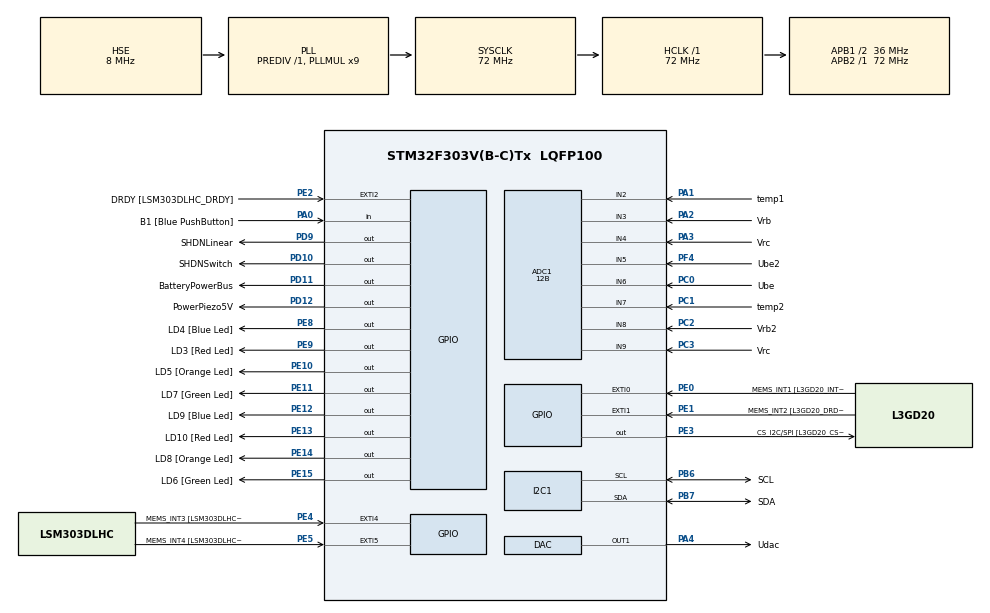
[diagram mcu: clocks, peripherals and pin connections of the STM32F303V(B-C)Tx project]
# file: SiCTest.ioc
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ADC1.AutoInjectedConv=DISABLE
ADC1.Channel-0\#ChannelRegularConversion=ADC_CHANNEL_2
ADC1.ClockPrescaler=ADC_CLOCK_ASYNC_DIV1
ADC1.ContinuousConvMode=DISABLE
ADC1.DMAContinuousRequests=DISABLE
ADC1.DataAlign=ADC_DATAALIGN_RIGHT
ADC1.DiscontinuousConvMode=DISABLE
ADC1.EOCSelection=ADC_EOC_SINGLE_CONV
ADC1.EnableAnalogWatchDog1=false
ADC1.EnableAnalogWatchDog2=false
ADC1.EnableAnalogWatchDog3=false
ADC1.EnableInjectedConversion=ENABLE
ADC1.EnableRegularConversion=ENABLE
ADC1.ExternalTrigConv=ADC_SOFTWARE_START
ADC1.ExternalTrigConvEdge=ADC_EXTERNALTRIGCONVEDGE_NONE
ADC1.InjNumberOfConversion=0
ADC1.InjectedDiscontinuousConvMode=DISABLE
ADC1.LowPowerAutoWait=DISABLE
ADC1.NbrOfConversion=1
ADC1.NbrOfConversionFlag=1
ADC1.Offset-0\#ChannelRegularConversion=0
ADC1.OffsetNumber-0\#ChannelRegularConversion=ADC_OFFSET_NONE
ADC1.Overrun=ADC_OVR_DATA_OVERWRITTEN
ADC1.Rank-0\#ChannelRegularConversion=1
ADC1.Resolution=ADC_RESOLUTION_12B
ADC1.SamplingTime-0\#ChannelRegularConversion=ADC_SAMPLETIME_1CYCLE_5
ADC1.ScanConvMode=ADC_SCAN_DISABLE
ADC1.SingleDiff-0\#ChannelRegularConversion=ADC_SINGLE_ENDED
ADC1.master=1
DAC.DAC_Channel=DAC_CHANNEL_1
DAC.WaveGeneration=DISABLE
I2C1.OwnAddress2Masks=I2C_OA2_NOMASK
I2C1.Timing=0x2000090E
Mcu.Family=STM32F3
Mcu.Name=STM32F303V(B-C)Tx
Mcu.Package=LQFP100
NVIC.PriorityGroup=NVIC_PRIORITYGROUP_0
PA0.GPIO_Label=B1 [Blue PushButton]
PA0.GPIO_Mode=GPIO_MODE_INPUT
PA0.GPIO_PuPd=GPIO_NOPULL
PA0.Signal=GPIO_Input
PA1.GPIO_Label=temp1
PA1.GPIO_PuPd=GPIO_NOPULL
PA1.Mode=IN2-Single-Ended
PA1.Signal=ADC1_IN2
PA11.GPIO_Label=DM
PA11.Signal=USB_DM
PA12.GPIO_Label=DP
PA12.Signal=USB_DP
PA13.Signal=SYS_JTMS-SWDIO
PA14.Signal=SYS_JTCK-SWCLK
PA2.GPIO_Label=Vrb
PA2.Mode=IN3-Single-Ended
PA2.Signal=ADC1_IN3
PA3.GPIO_Label=Vrc
PA3.Mode=IN4-Single-Ended
PA3.Signal=ADC1_IN4
PA4.GPIO_Label=Udac
PA4.Signal=COMP_DAC1_group
PA5.GPIO_Label=SPI1_SCK [L3GD20_SCL/SPC]
PA5.GPIO_Mode=GPIO_MODE_AF_PP
PA5.GPIO_PuPd=GPIO_NOPULL
PA5.GPIO_Speed=GPIO_SPEED_FREQ_LOW
PA5.Signal=SPI1_SCK
PA6.GPIO_Label=SPI1_MISO [L3GD20_SA0/SDO]
PA6.GPIO_Mode=GPIO_MODE_AF_PP
PA6.GPIO_PuPd=GPIO_NOPULL
PA6.GPIO_Speed=GPIO_SPEED_FREQ_LOW
PA6.Signal=SPI1_MISO
PA7.GPIO_Label=SPI1_MISO [L3GD20_SDA/SDI/SDO]
PA7.GPIO_Mode=GPIO_MODE_AF_PP
PA7.GPIO_PuPd=GPIO_NOPULL
PA7.GPIO_Speed=GPIO_SPEED_FREQ_LOW
PA7.Signal=SPI1_MOSI
PB3.Signal=SYS_JTDO-TRACESWO
PB6.GPIO_FM6=__NULL
PB6.GPIO_Label=SCL
PB6.GPIO_Mode=GPIO_MODE_AF_OD
PB6.GPIO_PuPd=GPIO_NOPULL
PB6.GPIO_Speed=GPIO_SPEED_FREQ_LOW
PB6.Mode=I2C
PB6.Signal=I2C1_SCL
PB7.GPIO_FM7=__NULL
PB7.GPIO_Label=SDA
PB7.GPIO_Mode=GPIO_MODE_AF_OD
PB7.GPIO_PuPd=GPIO_NOPULL
PB7.GPIO_Speed=GPIO_SPEED_FREQ_LOW
PB7.Mode=I2C
PB7.Signal=I2C1_SDA
PC0.GPIO_Label=Ube
PC0.Signal=ADCx_IN6
PC1.GPIO_Label=temp2
PC1.Signal=ADCx_IN7
PC14-OSC32_IN.GPIO_Label=OSC32_IN
PC14-OSC32_IN.Signal=RCC_OSC32_IN
PC15-OSC32_OUT.GPIO_Label=OSC32_OUT
PC15-OSC32_OUT.Signal=RCC_OSC32_OUT
PC2.GPIO_Label=Vrb2
PC2.Signal=ADCx_IN8
PC3.GPIO_Label=Vrc
PC3.Signal=ADCx_IN9
PD10.GPIO_Label=SHDNSwitch
PD10.GPIO_PuPd=GPIO_PULLUP
PD10.PinState=GPIO_PIN_SET
PD10.Signal=GPIO_Output
PD11.GPIO_Label=BatteryPowerBus
PD11.GPIO_PuPd=GPIO_PULLUP
PD11.PinState=GPIO_PIN_SET
PD11.Signal=GPIO_Output
PD12.GPIO_Label=PowerPiezo5V
PD12.GPIO_ModeDefaultOutputPP=GPIO_MODE_OUTPUT_PP
PD12.GPIO_PuPd=GPIO_NOPULL
PD12.PinState=GPIO_PIN_SET
PD12.Signal=GPIO_Output
PD9.GPIO_Label=SHDNLinear
PD9.GPIO_PuPd=GPIO_PULLUP
PD9.PinState=GPIO_PIN_SET
PD9.Signal=GPIO_Output
PE0.GPIO_Label=MEMS_INT1 [L3GD20_INT1]
PE0.GPIO_ModeDefaultEXTI=GPIO_MODE_EVT_RISING
PE0.GPIO_PuPd=GPIO_NOPULL
PE0.Signal=GPXTI0
PE1.GPIO_Label=MEMS_INT2 [L3GD20_DRDY/INT2]
PE1.GPIO_ModeDefaultEXTI=GPIO_MODE_EVT_RISING
PE1.GPIO_PuPd=GPIO_NOPULL
PE1.Signal=GPXTI1
PE10.GPIO_Label=LD5 [Orange Led]
PE10.GPIO_ModeDefaultOutputPP=GPIO_MODE_OUTPUT_PP
PE10.GPIO_PuPd=GPIO_NOPULL
PE10.GPIO_Speed=GPIO_SPEED_FREQ_LOW
PE10.Signal=GPIO_Output
PE11.GPIO_Label=LD7 [Green Led]
PE11.GPIO_ModeDefaultOutputPP=GPIO_MODE_OUTPUT_PP
PE11.GPIO_PuPd=GPIO_NOPULL
PE11.GPIO_Speed=GPIO_SPEED_FREQ_LOW
PE11.Signal=GPIO_Output
PE12.GPIO_Label=LD9 [Blue Led]
PE12.GPIO_ModeDefaultOutputPP=GPIO_MODE_OUTPUT_PP
PE12.GPIO_PuPd=GPIO_NOPULL
PE12.GPIO_Speed=GPIO_SPEED_FREQ_LOW
PE12.Signal=GPIO_Output
PE13.GPIO_Label=LD10 [Red Led]
PE13.GPIO_ModeDefaultOutputPP=GPIO_MODE_OUTPUT_PP
PE13.GPIO_PuPd=GPIO_NOPULL
PE13.GPIO_Speed=GPIO_SPEED_FREQ_LOW
PE13.Signal=GPIO_Output
PE14.GPIO_Label=LD8 [Orange Led]
PE14.GPIO_ModeDefaultOutputPP=GPIO_MODE_OUTPUT_PP
PE14.GPIO_PuPd=GPIO_NOPULL
PE14.GPIO_Speed=GPIO_SPEED_FREQ_LOW
PE14.Signal=GPIO_Output
PE15.GPIO_Label=LD6 [Green Led]
PE15.GPIO_ModeDefaultOutputPP=GPIO_MODE_OUTPUT_PP
PE15.GPIO_PuPd=GPIO_NOPULL
PE15.GPIO_Speed=GPIO_SPEED_FREQ_LOW
PE15.Signal=GPIO_Output
PE2.GPIO_Label=DRDY [LSM303DLHC_DRDY]
PE2.GPIO_ModeDefaultEXTI=GPIO_MODE_EVT_RISING
PE2.GPIO_PuPd=GPIO_NOPULL
PE2.Signal=GPXTI2
PE3.GPIO_Label=CS_I2C/SPI [L3GD20_CS_I2C/SPI]
PE3.GPIO_ModeDefaultOutputPP=GPIO_MODE_OUTPUT_PP
PE3.GPIO_PuPd=GPIO_NOPULL
PE3.GPIO_Speed=GPIO_SPEED_FREQ_LOW
PE3.Signal=GPIO_Output
PE4.GPIO_Label=MEMS_INT3 [LSM303DLHC_INT1]
PE4.GPIO_ModeDefaultEXTI=GPIO_MODE_EVT_RISING
PE4.GPIO_PuPd=GPIO_NOPULL
PE4.Signal=GPXTI4
PE5.GPIO_Label=MEMS_INT4 [LSM303DLHC_INT2]
PE5.GPIO_ModeDefaultEXTI=GPIO_MODE_EVT_RISING
PE5.GPIO_PuPd=GPIO_NOPULL
PE5.Signal=GPXTI5
PE8.GPIO_Label=LD4 [Blue Led]
PE8.GPIO_ModeDefaultOutputPP=GPIO_MODE_OUTPUT_PP
PE8.GPIO_PuPd=GPIO_NOPULL
PE8.GPIO_Speed=GPIO_SPEED_FREQ_LOW
PE8.Signal=GPIO_Output
PE9.GPIO_Label=LD3 [Red Led]
PE9.GPIO_ModeDefaultOutputPP=GPIO_MODE_OUTPUT_PP
PE9.GPIO_PuPd=GPIO_NOPULL
PE9.GPIO_Speed=GPIO_SPEED_FREQ_LOW
PE9.Signal=GPIO_Output
PF0-OSC_IN.Mode=HSE-External-Oscillator
PF0-OSC_IN.Signal=RCC_OSC_IN
PF1-OSC_OUT.GPIO_Label=OSC_OUT
PF1-OSC_OUT.Mode=HSE-External-Oscillator
PF1-OSC_OUT.Signal=RCC_OSC_OUT
PF4.GPIO_Label=Ube2
PF4.Mode=IN5-Single-Ended
PF4.Signal=ADC1_IN5
ProjectManager.HeapSize=0x200
ProjectManager.StackSize=0x400
ProjectManager.TargetToolchain=EWARM
RCC.ADC1Enable=true
RCC.ADC2Enable=false
RCC.ADC3Enable=false
RCC.ADC4Enable=false
RCC.AHBCLKDivider=RCC_SYSCLK_DIV1
RCC.AHBFreq_Value=72000000
RCC.APB1CLKDivider=RCC_HCLK_DIV2
RCC.APB1Freq_Value=36000000
RCC.APB1TimFreq_Value=72000000
RCC.APB2Freq_Value=72000000
RCC.APB2TimFreq_Value=72000000
RCC.ClockTypeHCLK=RCC_CLOCKTYPE_HCLK
RCC.ClockTypePCLK1=RCC_CLOCKTYPE_PCLK1
RCC.ClockTypePCLK2=RCC_CLOCKTYPE_PCLK2
RCC.CortexFreq_Value=72000000
RCC.EnableHSE=true
RCC.EnableHSERTCDevisor=false
RCC.EnableHSIRTCDevisor=false
RCC.EnableLSE=false
RCC.EnableLSERTC=false
RCC.EnableMCOMultDivisor=false
RCC.EnbaleCSS=true
RCC.FLITFCLKFEnable=false
RCC.HCLKFreq_Value=72000000
RCC.HRTIMEnable=false
RCC.HSEState=RCC_HSE_ON
RCC.HSE_VALUE=8000000
RCC.HSIState=RCC_HSI_ON
RCC.HSI_VALUE=8000000
RCC.I2C1Enable=true
RCC.I2C2Enable=false
RCC.I2C3Enable=false
RCC.I2SEnable=false
RCC.IWDGEnable=false
RCC.LSE_VALUE=32768
RCC.LSIState=RCC_LSI_OFF
RCC.MCOEnable=false
RCC.OscillatorTypeHSE=RCC_OSCILLATORTYPE_HSE
RCC.OscillatorTypeHSI=RCC_OSCILLATORTYPE_HSI
RCC.PLLMUL=RCC_PLL_MUL9
RCC.PLLSource=RCC_PLLSOURCE_HSE
RCC.PLLSourceVirtual=RCC_PLLSOURCE_HSE
RCC.PLLState=RCC_PLL_ON
RCC.RCC_PERIPHCLK_I2C1Var=RCC_PERIPHCLK_I2C1
RCC.RTCEnable=false
RCC.SYSCLKFreq_VALUE=72000000
RCC.SYSCLKSource=RCC_SYSCLKSOURCE_PLLCLK
RCC.SYSCLKSourceVirtual=RCC_SYSCLKSOURCE_PLLCLK
RCC.Tim15Enable=false
RCC.Tim16Enable=false
RCC.Tim17Enable=false
RCC.Tim1Enable=false
RCC.Tim8Enable=false
RCC.UART4Enable=false
RCC.UART5Enable=false
RCC.USART1Enable=false
RCC.USART2Enable=false
RCC.USART3Enable=false
RCC.USBEnable=false
RCC.USBFreq_Value=72000000
SH.ADCx_IN6.0=ADC1_IN6,IN6-Single-Ended
SH.ADCx_IN7.0=ADC1_IN7,IN7-Single-Ended
SH.ADCx_IN8.0=ADC1_IN8,IN8-Single-Ended
SH.ADCx_IN9.0=ADC1_IN9,IN9-Single-Ended
SH.COMP_DAC1_group.0=DAC_OUT1,DAC_OUT1
VP_ADC1_Vref_Input.Mode=IN-Vrefint
board=STM32F3DISCOVERY

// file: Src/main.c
/**
  ******************************************************************************
  * File Name          : main.c
  * Description        : Test program that will simulate the OBC onboard the MIST Satellite
  ******************************************************************************
  *

    This is a test program which has the purpose to simulate the OBC onboard the MIST satellite.
    The main program will start sending commands via I2C to the SiC MCU for which message it
    sends will test the functions that are implemented on the hardware of the SiC PCB.

  * COPYRIGHT(c) 2017 STMicroelectronics
  *
  * Redistribution and use in source and binary forms, with or without modification,
  * are permitted provided that the following conditions are met:
  *   1. Redistributions of source code must retain the above copyright notice,
  *      this list of conditions and the following disclaimer.
  *   2. Redistributions in binary form must reproduce the above copyright notice,
  *      this list of conditions and the following disclaimer in the documentation
  *      and/or other materials provided with the distribution.
  *   3. Neither the name of STMicroelectronics nor the names of its contributors
  *      may be used to endorse or promote products derived from this software
  *      without specific prior written permission.
  *
  * THIS SOFTWARE IS PROVIDED BY THE COPYRIGHT HOLDERS AND CONTRIBUTORS "AS IS"
  * AND ANY EXPRESS OR IMPLIED WARRANTIES, INCLUDING, BUT NOT LIMITED TO, THE
  * IMPLIED WARRANTIES OF MERCHANTABILITY AND FITNESS FOR A PARTICULAR PURPOSE ARE
  * DISCLAIMED. IN NO EVENT SHALL THE COPYRIGHT HOLDER OR CONTRIBUTORS BE LIABLE
  * FOR ANY DIRECT, INDIRECT, INCIDENTAL, SPECIAL, EXEMPLARY, OR CONSEQUENTIAL
  * DAMAGES (INCLUDING, BUT NOT LIMITED TO, PROCUREMENT OF SUBSTITUTE GOODS OR
  * SERVICES; LOSS OF USE, DATA, OR PROFITS; OR BUSINESS INTERRUPTION) HOWEVER
  * CAUSED AND ON ANY THEORY OF LIABILITY, WHETHER IN CONTRACT, STRICT LIABILITY,
  * OR TORT (INCLUDING NEGLIGENCE OR OTHERWISE) ARISING IN ANY WAY OUT OF THE USE
  * OF THIS SOFTWARE, EVEN IF ADVISED OF THE POSSIBILITY OF SUCH DAMAGE.
  *
  ******************************************************************************
  */
#include "main.h"
#include "stm32f3xx_hal.h"
#include "functions.h"

ADC_HandleTypeDef hadc1;

DAC_HandleTypeDef hdac;

I2C_HandleTypeDef hi2c1;

/* USER CODE BEGIN PV */
/* Private variables ---------------------------------------------------------*/

/* USER CODE END PV */

void SystemClock_Config(void);
void Error_Handler(void);
static void MX_GPIO_Init(void);
static void MX_ADC1_Init(void);
static void MX_DAC_Init(void);
static void MX_I2C1_Init(void);

/* USER CODE BEGIN PFP */
/* Private function prototypes -----------------------------------------------*/
extern experiment_package experiments[8];

/* USER CODE END PFP */

int main(void)
{

  /* MCU Configuration----------------------------------------------------------*/

  /* Reset of all peripherals, Initializes the Flash interface and the Systick. */
  HAL_Init();

  /* Configure the system clock */
  SystemClock_Config();

  /* Initialize all configured peripherals */
  MX_GPIO_Init();
  MX_ADC1_Init();
  MX_DAC_Init();
  MX_I2C1_Init();

  while(1)
  {
   // To start the test program push the User Button on the board
     User_Button();
   // Test function that will test all the functions on the SiC PCB
     Test_SiC();

}

}

/** System Clock Configuration
*/
void SystemClock_Config(void)
{

  RCC_OscInitTypeDef RCC_OscInitStruct;
  RCC_ClkInitTypeDef RCC_ClkInitStruct;
  RCC_PeriphCLKInitTypeDef PeriphClkInit;

    /**Initializes the CPU, AHB and APB busses clocks
    */
  RCC_OscInitStruct.OscillatorType = RCC_OSCILLATORTYPE_HSI|RCC_OSCILLATORTYPE_HSE;
  RCC_OscInitStruct.HSEState = RCC_HSE_ON;
  RCC_OscInitStruct.HSEPredivValue = RCC_HSE_PREDIV_DIV1;
  RCC_OscInitStruct.HSIState = RCC_HSI_ON;
  RCC_OscInitStruct.HSICalibrationValue = 16;
  RCC_OscInitStruct.PLL.PLLState = RCC_PLL_ON;
  RCC_OscInitStruct.PLL.PLLSource = RCC_PLLSOURCE_HSE;
  RCC_OscInitStruct.PLL.PLLMUL = RCC_PLL_MUL9;
  if (HAL_RCC_OscConfig(&RCC_OscInitStruct) != HAL_OK)
  {
    Error_Handler();
  }

    /**Initializes the CPU, AHB and APB busses clocks
    */
  RCC_ClkInitStruct.ClockType = RCC_CLOCKTYPE_HCLK|RCC_CLOCKTYPE_SYSCLK
                              |RCC_CLOCKTYPE_PCLK1|RCC_CLOCKTYPE_PCLK2;
  RCC_ClkInitStruct.SYSCLKSource = RCC_SYSCLKSOURCE_PLLCLK;
  RCC_ClkInitStruct.AHBCLKDivider = RCC_SYSCLK_DIV1;
  RCC_ClkInitStruct.APB1CLKDivider = RCC_HCLK_DIV2;
  RCC_ClkInitStruct.APB2CLKDivider = RCC_HCLK_DIV1;

  if (HAL_RCC_ClockConfig(&RCC_ClkInitStruct, FLASH_LATENCY_2) != HAL_OK)
  {
    Error_Handler();
  }

  PeriphClkInit.PeriphClockSelection = RCC_PERIPHCLK_I2C1|RCC_PERIPHCLK_ADC12;
  PeriphClkInit.Adc12ClockSelection = RCC_ADC12PLLCLK_DIV1;
  PeriphClkInit.I2c1ClockSelection = RCC_I2C1CLKSOURCE_HSI;
  if (HAL_RCCEx_PeriphCLKConfig(&PeriphClkInit) != HAL_OK)
  {
    Error_Handler();
  }

    /**Enables the Clock Security System
    */
  HAL_RCC_EnableCSS();

    /**Configure the Systick interrupt time
    */
  HAL_SYSTICK_Config(HAL_RCC_GetHCLKFreq()/1000);

    /**Configure the Systick
    */
  HAL_SYSTICK_CLKSourceConfig(SYSTICK_CLKSOURCE_HCLK);

  /* SysTick_IRQn interrupt configuration */
  HAL_NVIC_SetPriority(SysTick_IRQn, 0, 0);
}

/* ADC1 init function */
static void MX_ADC1_Init(void)
{

  ADC_MultiModeTypeDef multimode;
  ADC_ChannelConfTypeDef sConfig;

    /**Common config
    */
  hadc1.Instance = ADC1;
  hadc1.Init.ClockPrescaler = ADC_CLOCK_ASYNC_DIV1;
  hadc1.Init.Resolution = ADC_RESOLUTION_12B;
  hadc1.Init.ScanConvMode = ADC_SCAN_DISABLE;
  hadc1.Init.ContinuousConvMode = DISABLE;
  hadc1.Init.DiscontinuousConvMode = DISABLE;
  hadc1.Init.ExternalTrigConvEdge = ADC_EXTERNALTRIGCONVEDGE_NONE;
  hadc1.Init.ExternalTrigConv = ADC_SOFTWARE_START;
  hadc1.Init.DataAlign = ADC_DATAALIGN_RIGHT;
  hadc1.Init.NbrOfConversion = 1;
  hadc1.Init.DMAContinuousRequests = DISABLE;
  hadc1.Init.EOCSelection = ADC_EOC_SINGLE_CONV;
  hadc1.Init.LowPowerAutoWait = DISABLE;
  hadc1.Init.Overrun = ADC_OVR_DATA_OVERWRITTEN;
  if (HAL_ADC_Init(&hadc1) != HAL_OK)
  {
    Error_Handler();
  }

    /**Configure the ADC multi-mode
    */
  multimode.Mode = ADC_MODE_INDEPENDENT;
  if (HAL_ADCEx_MultiModeConfigChannel(&hadc1, &multimode) != HAL_OK)
  {
    Error_Handler();
  }

    /**Configure Regular Channel
    */
  sConfig.Channel = ADC_CHANNEL_2;
  sConfig.Rank = 1;
  sConfig.SingleDiff = ADC_SINGLE_ENDED;
  sConfig.SamplingTime = ADC_SAMPLETIME_1CYCLE_5;
  sConfig.OffsetNumber = ADC_OFFSET_NONE;
  sConfig.Offset = 0;
  if (HAL_ADC_ConfigChannel(&hadc1, &sConfig) != HAL_OK)
  {
    Error_Handler();
  }
  /*
sConfig.Channel = ADC_CHANNEL_3;
	if(HAL_ADC_ConfigChannel(&hadc1, &sConfig) != HAL_OK){
		 Error_Handler();
	}

		sConfig.Channel = ADC_CHANNEL_5;
	if(HAL_ADC_ConfigChannel(&hadc1, &sConfig) != HAL_OK){
		 Error_Handler();
	}
		sConfig.Channel = ADC_CHANNEL_6;
	if(HAL_ADC_ConfigChannel(&hadc1, &sConfig) != HAL_OK){
		 Error_Handler();
	}
		sConfig.Channel = ADC_CHANNEL_7;
	if(HAL_ADC_ConfigChannel(&hadc1, &sConfig) != HAL_OK){
		 Error_Handler();
	}

		sConfig.Channel = ADC_CHANNEL_8;
	if(HAL_ADC_ConfigChannel(&hadc1, &sConfig) != HAL_OK){
		 Error_Handler();
	}

	sConfig.Channel = ADC_CHANNEL_9;
	if(HAL_ADC_ConfigChannel(&hadc1, &sConfig) != HAL_OK){
		 Error_Handler();
	}
*/
}

/* DAC init function */
static void MX_DAC_Init(void)
{

  DAC_ChannelConfTypeDef sConfig;

    /**DAC Initialization
    */
  hdac.Instance = DAC;
  if (HAL_DAC_Init(&hdac) != HAL_OK)
  {
    Error_Handler();
  }

    /**DAC channel OUT1 config
    */
  sConfig.DAC_Trigger = DAC_TRIGGER_NONE;
  sConfig.DAC_OutputBuffer = DAC_OUTPUTBUFFER_ENABLE;
  if (HAL_DAC_ConfigChannel(&hdac, &sConfig, DAC_CHANNEL_1) != HAL_OK)
  {
    Error_Handler();
  }

}

/* I2C1 init function */
static void MX_I2C1_Init(void)
{

  hi2c1.Instance = I2C1;
  hi2c1.Init.Timing = 0x2000090E;
  hi2c1.Init.OwnAddress1 = 0x20;
  hi2c1.Init.AddressingMode = I2C_ADDRESSINGMODE_7BIT;
  hi2c1.Init.DualAddressMode = I2C_DUALADDRESS_DISABLE;
  hi2c1.Init.OwnAddress2 = 0;
  hi2c1.Init.OwnAddress2Masks = I2C_OA2_NOMASK;
  hi2c1.Init.GeneralCallMode = I2C_GENERALCALL_DISABLE;
  hi2c1.Init.NoStretchMode = I2C_NOSTRETCH_DISABLE;
  if (HAL_I2C_Init(&hi2c1) != HAL_OK)
  {
    Error_Handler();
  }

    /**Configure Analogue filter
    */
  if (HAL_I2CEx_ConfigAnalogFilter(&hi2c1, I2C_ANALOGFILTER_ENABLE) != HAL_OK)
  {
    Error_Handler();
  }

    /**Configure Digital filter
    */
  if (HAL_I2CEx_ConfigDigitalFilter(&hi2c1, 0) != HAL_OK)
  {
    Error_Handler();
  }

}

/** Configure pins as
        * Analog
        * Input
        * Output
        * EVENT_OUT
        * EXTI
     PA5   ------> SPI1_SCK
     PA6   ------> SPI1_MISO
     PA7   ------> SPI1_MOSI
     PA11   ------> USB_DM
     PA12   ------> USB_DP
*/
static void MX_GPIO_Init(void)
{

  GPIO_InitTypeDef GPIO_InitStruct;

  /* GPIO Ports Clock Enable */
  __HAL_RCC_GPIOE_CLK_ENABLE();
  __HAL_RCC_GPIOC_CLK_ENABLE();
  __HAL_RCC_GPIOF_CLK_ENABLE();
  __HAL_RCC_GPIOA_CLK_ENABLE();
  __HAL_RCC_GPIOD_CLK_ENABLE();
  __HAL_RCC_GPIOB_CLK_ENABLE();

  /*Configure GPIO pin Output Level */
  HAL_GPIO_WritePin(GPIOE, CS_I2C_SPI_Pin|LD4_Pin|LD3_Pin|LD5_Pin
                          |LD7_Pin|LD9_Pin|LD10_Pin|LD8_Pin
                          |LD6_Pin, GPIO_PIN_RESET);

  /*Configure GPIO pin Output Level */
  HAL_GPIO_WritePin(GPIOD, SHDNLinear_Pin|SHDNSwitch_Pin|BatteryPowerBus_Pin|PowerPiezo5V_Pin, GPIO_PIN_SET);

  /*Configure GPIO pins : DRDY_Pin MEMS_INT3_Pin MEMS_INT4_Pin MEMS_INT1_Pin
                           MEMS_INT2_Pin */
  GPIO_InitStruct.Pin = DRDY_Pin|MEMS_INT3_Pin|MEMS_INT4_Pin|MEMS_INT1_Pin
                          |MEMS_INT2_Pin;
  GPIO_InitStruct.Mode = GPIO_MODE_EVT_RISING;
  GPIO_InitStruct.Pull = GPIO_NOPULL;
  HAL_GPIO_Init(GPIOE, &GPIO_InitStruct);

  /*Configure GPIO pins : CS_I2C_SPI_Pin LD4_Pin LD3_Pin LD5_Pin
                           LD7_Pin LD9_Pin LD10_Pin LD8_Pin
                           LD6_Pin */
  GPIO_InitStruct.Pin = CS_I2C_SPI_Pin|LD4_Pin|LD3_Pin|LD5_Pin
                          |LD7_Pin|LD9_Pin|LD10_Pin|LD8_Pin
                          |LD6_Pin;
  GPIO_InitStruct.Mode = GPIO_MODE_OUTPUT_PP;
  GPIO_InitStruct.Pull = GPIO_NOPULL;
  GPIO_InitStruct.Speed = GPIO_SPEED_FREQ_LOW;
  HAL_GPIO_Init(GPIOE, &GPIO_InitStruct);

  /*Configure GPIO pin : B1_Pin */
  GPIO_InitStruct.Pin = B1_Pin;
  GPIO_InitStruct.Mode = GPIO_MODE_INPUT;
  GPIO_InitStruct.Pull = GPIO_NOPULL;
  HAL_GPIO_Init(B1_GPIO_Port, &GPIO_InitStruct);

  /*Configure GPIO pins : SPI1_SCK_Pin SPI1_MISO_Pin SPI1_MISOA7_Pin */
  GPIO_InitStruct.Pin = SPI1_SCK_Pin|SPI1_MISO_Pin|SPI1_MISOA7_Pin;
  GPIO_InitStruct.Mode = GPIO_MODE_AF_PP;
  GPIO_InitStruct.Pull = GPIO_NOPULL;
  GPIO_InitStruct.Speed = GPIO_SPEED_FREQ_LOW;
  GPIO_InitStruct.Alternate = GPIO_AF5_SPI1;
  HAL_GPIO_Init(GPIOA, &GPIO_InitStruct);

  /*Configure GPIO pins : SHDNLinear_Pin SHDNSwitch_Pin BatteryPowerBus_Pin */
  GPIO_InitStruct.Pin = SHDNLinear_Pin|SHDNSwitch_Pin|BatteryPowerBus_Pin;
  GPIO_InitStruct.Mode = GPIO_MODE_OUTPUT_PP;
  GPIO_InitStruct.Pull = GPIO_PULLUP;
  GPIO_InitStruct.Speed = GPIO_SPEED_FREQ_LOW;
  HAL_GPIO_Init(GPIOD, &GPIO_InitStruct);

  /*Configure GPIO pin : PowerPiezo5V_Pin */
  GPIO_InitStruct.Pin = PowerPiezo5V_Pin;
  GPIO_InitStruct.Mode = GPIO_MODE_OUTPUT_PP;
  GPIO_InitStruct.Pull = GPIO_NOPULL;
  GPIO_InitStruct.Speed = GPIO_SPEED_FREQ_LOW;
  HAL_GPIO_Init(PowerPiezo5V_GPIO_Port, &GPIO_InitStruct);

  /*Configure GPIO pins : DM_Pin DP_Pin */
  GPIO_InitStruct.Pin = DM_Pin|DP_Pin;
  GPIO_InitStruct.Mode = GPIO_MODE_AF_PP;
  GPIO_InitStruct.Pull = GPIO_NOPULL;
  GPIO_InitStruct.Speed = GPIO_SPEED_FREQ_HIGH;
  GPIO_InitStruct.Alternate = GPIO_AF14_USB;
  HAL_GPIO_Init(GPIOA, &GPIO_InitStruct);

}

void Error_Handler(void)
{
    HAL_GPIO_WritePin(LD6_GPIO_Port, LD6_Pin, GPIO_PIN_SET);
    return;
}

/************************ (C) COPYRIGHT STMicroelectronics *****END OF FILE****/
